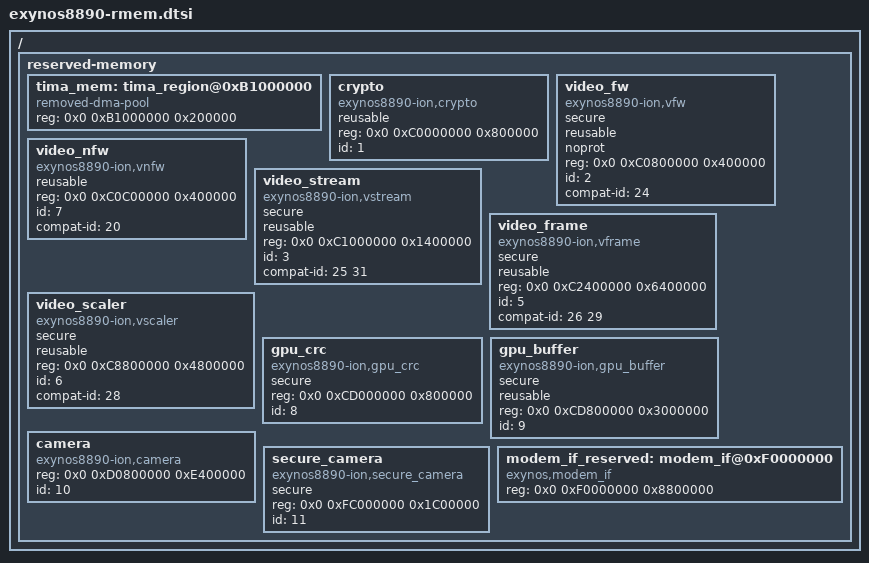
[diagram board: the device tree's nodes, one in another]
/*
 * SAMSUNG EXYNOS device tree source for reserved-memory
 *
 * Copyright (c) 2015 Samsung Electronics Co., Ltd.
 *		http://www.samsung.com
 *
 * This program is free software; you can redistribute it and/or modify
 * it under the terms of the GNU General Public License version 2 as
 * published by the Free Software Foundation.
*/

/ {
	reserved-memory {
		#address-cells = <2>;
		#size-cells = <1>;
		ranges;

		tima_mem: tima_region@0xB1000000 {
			compatible = "removed-dma-pool";
			reg = <0x0 0xB1000000 0x200000>;
		};

		crypto {
			compatible = "exynos8890-ion,crypto";
			reusable;
			reg = <0x0 0xC0000000 0x800000>;
			id = <1>;
		};

		video_fw {
			compatible = "exynos8890-ion,vfw";
			secure;
			reusable;
			noprot;
			reg = <0x0 0xC0800000 0x400000>;
			id = <2>;
			compat-id = <24>;
		};

		video_nfw {
			compatible = "exynos8890-ion,vnfw";
			reusable;
			reg = <0x0 0xC0C00000 0x400000>;
			id = <7>;
			compat-id = <20>;
		};

		video_stream {
			compatible = "exynos8890-ion,vstream";
			secure;
			reusable;
			reg = <0x0 0xC1000000 0x1400000>;
			id = <3>;
			compat-id = <25 31>;
		};

		video_frame {
			compatible = "exynos8890-ion,vframe";
			secure;
			reusable;
			reg = <0x0 0xC2400000 0x6400000>;
			id = <5>;
			compat-id = <26 29>;
		};

		video_scaler {
			compatible = "exynos8890-ion,vscaler";
			secure;
			reusable;
			reg = <0x0 0xC8800000 0x4800000>;
			id = <6>;
			compat-id = <28>;
		};

		gpu_crc {
			compatible = "exynos8890-ion,gpu_crc";
			secure;
			reg = <0x0 0xCD000000 0x800000>;
			id = <8>;
		};

		gpu_buffer {
			compatible = "exynos8890-ion,gpu_buffer";
			secure;
			reusable;
			reg = <0x0 0xCD800000 0x3000000>;
			id = <9>;
		};

		camera {
			compatible = "exynos8890-ion,camera";
			reg = <0x0 0xD0800000 0xE400000>;
			id = <10>;
		};

		secure_camera {
			compatible = "exynos8890-ion,secure_camera";
			secure;
			reg = <0x0 0xFC000000 0x1C00000>;
			id = <11>;
		};

		modem_if_reserved: modem_if@0xF0000000 {
			compatible = "exynos,modem_if";
			reg = <0x0 0xF0000000 0x8800000>;
		};
	};
};
